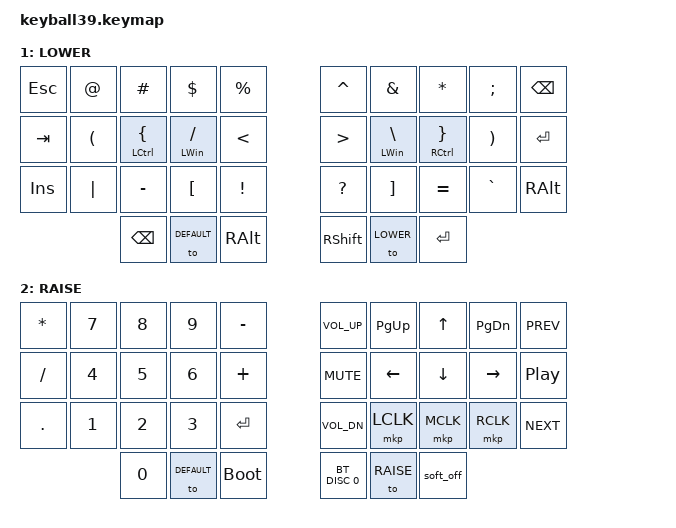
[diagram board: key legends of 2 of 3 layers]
#include <behaviors.dtsi>
#include <behaviors/mouse_keys.dtsi>
#include <dt-bindings/zmk/bt.h>
#include <dt-bindings/zmk/mouse.h>
#include <dt-bindings/zmk/keys.h>
#include <dt-bindings/zmk/outputs.h>

#define DEFAULT 0
#define LOWER   1
#define RAISE   2
#define ZMK_MOUSE_DEFAULT_SCRL_VAL 50

// Handy to use these tap/holds

&mt {
    flavor = "balanced";
    tapping-term-ms = <800>;
};

&lt {
    flavor = "balanced";
    tapping-term-ms = <150>;
};

/ {
    behaviors {
        /* This is still in an open PR - https://github.com/zmkfirmware/zmk/pull/2027*/
        volume_encoder: volume_encoder {
            compatible = "zmk,behavior-sensor-rotate";
            #sensor-binding-cells = <0>;
            bindings = <&kp C_VOL_UP>, <&kp C_VOL_DN>;
        };
        selection_encoder: selection_encoder {
            compatible = "zmk,behavior-sensor-rotate";
            #sensor-binding-cells = <0>;
            bindings = <&kp LS(DOWN)>, <&kp LS(UP)>;
        };
        scroll_encoder: scroll_encoder {
	        compatible = "zmk,behavior-sensor-rotate";
            #sensor-binding-cells = <0>;
            tap-ms = <100>;
            bindings = <&msc SCRL_UP>, <&msc SCRL_DOWN>;
        };
    };
    
    keymap {
        compatible = "zmk,keymap";

        default_layer {
            bindings = < 
&kp Q           &kp W           &kp E           &kp R           &kp T                                           &kp Y           &kp U           &kp I           &kp O           &kp P
&kp A           &kp S           &mt LCTRL D     &mt LWIN F      &kp G                                           &kp H           &mt LWIN J      &mt RCTRL K     &kp L           &kp RET
&kp LSHFT       &kp Z           &kp X           &kp C           &kp V                                           &kp B           &kp N           &kp M           &kp COMMA       &kp DOT
&kp LCTRL       &kp LALT        &kp LWIN          &mt LALT TAB    &lt LOWER SPACE  &mt LWIN TAB           &mt LSHFT BSPC   &mkp LCLK                                      &lt RAISE SEMI
            >;
            sensor-bindings = <&scroll_encoder>;
        };

        LOWER {
            bindings = <
&kp ESC         &kp AT          &kp POUND       &kp DOLLAR      &kp PRCNT                       &kp CARET       &kp AMPS        &kp ASTRK       &kp SEMI        &kp BSPC
&kp TAB         &kp LPAR        &mt LCTRL LBRC  &mt LWIN FSLH   &kp LT                          &kp GT          &mt LWIN BSLH   &mt RCTRL RBRC  &kp RPAR        &kp ENTER
&kp INS         &kp PIPE        &kp MINUS       &kp LBKT        &kp EXCL                        &kp QMARK       &kp RBKT        &kp EQUAL       &kp GRAVE       &kp RALT
&kp BSPC                                        &to DEFAULT     &kp RALT        &kp RSHFT       &to LOWER                                                       &kp RET
            >;
            sensor-bindings = <&selection_encoder>;
        };

        RAISE {
            bindings = <
&kp ASTRK       &kp N7          &kp N8          &kp N9          &kp MINUS                       &kp C_VOL_UP    &kp PAGE_UP     &kp UP          &kp PAGE_DOWN   &kp C_PREV
&kp FSLH        &kp N4          &kp N5          &kp N6          &kp PLUS                        &kp C_MUTE      &kp LEFT        &kp DOWN        &kp RIGHT       &kp C_PP
&kp DOT         &kp N1          &kp N2          &kp N3          &kp ENTER                       &kp C_VOL_DN    &mkp LCLK       &mkp MCLK       &mkp RCLK       &kp C_NEXT
&kp N0                                          &to DEFAULT     &bootloader     &bt BT_DISC 0   &to RAISE                                                       &soft_off
            >;
            sensor-bindings = <&volume_encoder>;
        };
    };
};
